# nrf9120_mlm1_modem register map
Vendor: Nordic Semiconductor; Series: nrf91; File version: 1
CPU: CM4 r0p1, little endian, MPU, no FPU, 3 interrupt priority bits
Registers are 32-bit, read-write, reset 0x0 unless marked. A register's access mark holds for its fields unless they carry their own. Offsets are from the block's base; [hi:lo] are bit positions; 'fields as' and 'values as' point back to an identical list.

## DCLOCK — Clock Management
Base 0x40015000
0x00 TASKS_HFCLKSTART wo — Start HFCLK crystal oscillator
  [0] TASKS_HFCLKSTART
    1=Trigger task
0x04 TASKS_HFCLKSTOP wo — Stop HFCLK crystal oscillator
  [0] TASKS_HFCLKSTOP
    1=Trigger task
0x08 TASKS_LFCLKSTART wo — Start LFCLK source
  [0] TASKS_LFCLKSTART
    1=Trigger task
0x0C TASKS_LFCLKSTOP wo — Stop LFCLK source
  [0] TASKS_LFCLKSTOP
    1=Trigger task
0x100 EVENTS_HFCLKSTARTED — HFCLK oscillator started
  [0] EVENTS_HFCLKSTARTED
    0=NotGenerated (Event not generated); 1=Generated (Event generated)
0x104 EVENTS_LFCLKSTARTED — LFCLK started
  [0] EVENTS_LFCLKSTARTED
    values as EVENTS_HFCLKSTARTED.EVENTS_HFCLKSTARTED
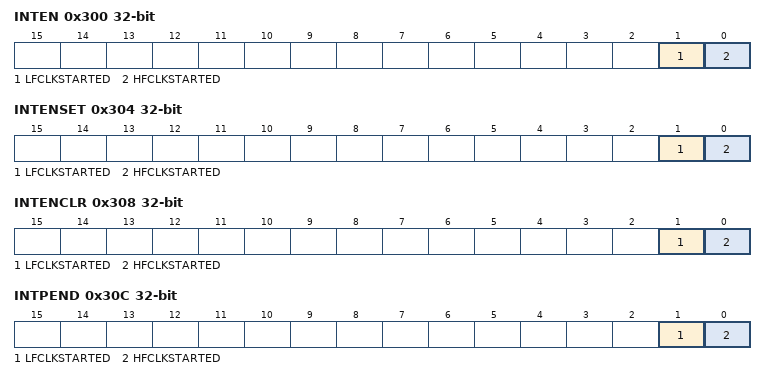
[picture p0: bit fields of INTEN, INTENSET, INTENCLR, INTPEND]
0x300 INTEN — Enable or disable interrupt
  [1] LFCLKSTARTED — Enable or disable interrupt for event LFCLKSTARTED
    0=Disabled; 1=Enabled
  [0] HFCLKSTARTED — Enable or disable interrupt for event HFCLKSTARTED
    0=Disabled; 1=Enabled
0x304 INTENSET — Enable interrupt
  [1] LFCLKSTARTED — Write '1' to enable interrupt for event LFCLKSTARTED
    on read: 0=Disabled (Read: Disabled); 1=Enabled (Read: Enabled) | on write: 1=Set (Enable)
  [0] HFCLKSTARTED — Write '1' to enable interrupt for event HFCLKSTARTED
    values as LFCLKSTARTED
0x308 INTENCLR — Disable interrupt
  [1] LFCLKSTARTED — Write '1' to disable interrupt for event LFCLKSTARTED
    on read: 0=Disabled (Read: Disabled); 1=Enabled (Read: Enabled) | on write: 1=Clear (Disable)
  [0] HFCLKSTARTED — Write '1' to disable interrupt for event HFCLKSTARTED
    values as LFCLKSTARTED
0x30C INTPEND ro — Pending interrupts
  [1] LFCLKSTARTED — Read pending status of interrupt for event LFCLKSTARTED
    on read: 0=NotPending (Read: Not pending); 1=Pending (Read: Pending)
  [0] HFCLKSTARTED — Read pending status of interrupt for event HFCLKSTARTED
    values as LFCLKSTARTED
0x408 HFCLKRUN ro — Status indicating that HFCLKSTART task has been triggered
  [0] STATUS — HFCLKSTART task triggered or not
    0=NotTriggered (Task not triggered); 1=Triggered (Task triggered)
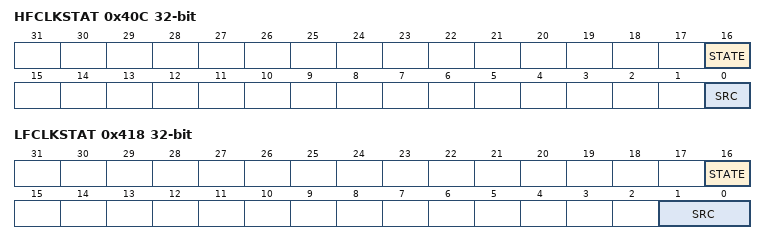
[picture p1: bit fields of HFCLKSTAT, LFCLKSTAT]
0x40C HFCLKSTAT ro — Which HFCLK source is running
  [16] STATE — HFCLK state
    0=NotRunning (HFCLK not running); 1=Running (HFCLK running)
  [0] SRC — Active clock source
    0=HFINT (HFCLK clock source: HFINT - 64 MHz on-chip oscillator); 1=HFXO (HFCLK clock source: HFXO - 64 MHz clock derived from external 32 MHz crystal oscillator)
0x414 LFCLKRUN ro — Status indicating that LFCLKSTART task has been triggered
  [0] STATUS — LFCLKSTART task triggered or not
    values as HFCLKRUN.STATUS
0x418 LFCLKSTAT ro — Which LFCLK source is running
  [16] STATE — LFCLK state
    0=NotRunning (LFCLK not running); 1=Running (LFCLK running)
  [1:0] SRC — Active clock source
    0=LFULP (32.768 kHz ultra low power RC oscillator); 1=LFRC (32.768 kHz RC oscillator); 2=LFXO (32.768 kHz crystal oscillator); 3=LFSYNT (32.768 kHz synthesized from HFCLK)
0x41C LFCLKSRCCOPY ro — Copy of LFCLKSRC register, set when LFCLKSTART task was triggered LFULP is not treat as a separate clock source on Alta MLM1, where default clock source (0) is LFRC.
  [1:0] SRC — Clock source
    0=LFULP (32.768 kHz ultra low power RC oscillator (default)); 1=LFRC (32.768 kHz RC oscillator); 2=LFXO (32.768 kHz crystal oscillator); 3=LFSYNT (32.768 kHz synthesized from HFCLK)
0x430 HFCLKCURRFREQ — Current frequency of HFCLK
  [7:0] HFCLKCURRFREQ — Current High frequency clock (HCLK) frequency
    0=Default frequency
0x514 HFCLKSRC reset 0x100001 — Clock source for the HFCLK oscillator, and configuration of XTAL oscillator. This register shall only be written while no oscillation is present on XC1. Failing to do so may cause unexpected behaviour.
  [0] SRC — Select which HFCLK source is started by the START task
    0=HFINT (HFCLKSTART task starts HFINT oscillator); 1=HFXO (HFCLKSTART task starts HFXO oscillator)
0x518 LFCLKSRC — Clock source for the LFCLK. LFCLKSTART task starts starts a clock source selected with this register. LFULP is not treat as a separate clock source on Alta MLM1, where default clock source (0) is LFRC.
  fields as LFCLKSRCCOPY
0x558 HFCLKCTRL — HFCLK frequency configuration.
  [7:0] HCLK — High frequency clock HCLK
    0=Default frequency
